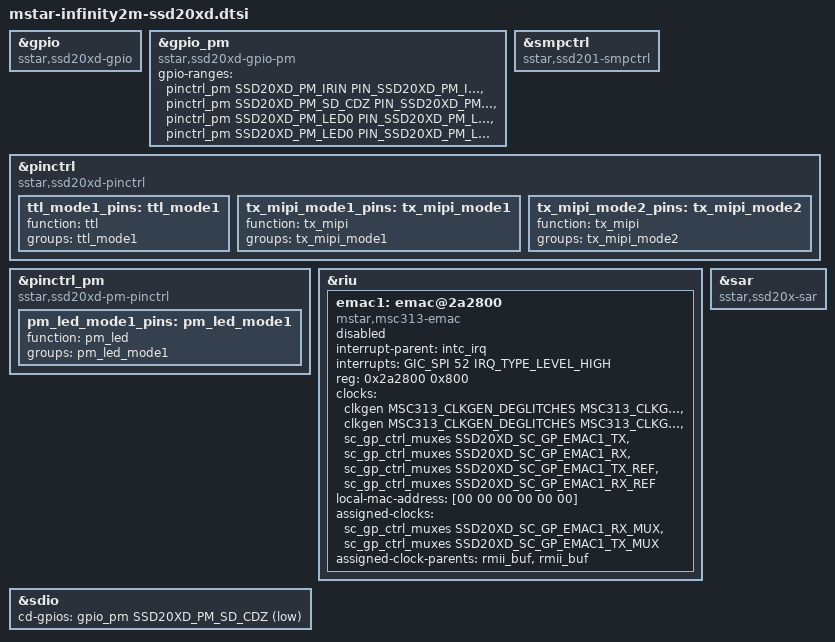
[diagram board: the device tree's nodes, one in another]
// SPDX-License-Identifier: GPL-2.0-or-later
/*
 * Copyright (c) 2020 thingy.jp.
 * Author: Daniel Palmer <daniel@thingy.jp>
 */

#include <dt-bindings/gpio/msc313-gpio-pm.h>
#include <dt-bindings/pinctrl/mstar.h>
#include <dt-bindings/clock/mstar-msc313-sc-gp.h>

#include "mstar-infinity2m.dtsi"

&gpio {
	compatible = "sstar,ssd20xd-gpio";
	/delete-property/ gpio-ranges;
	status = "okay";
};

&gpio_pm {
	compatible = "sstar,ssd20xd-gpio-pm";
	gpio-ranges = <&pinctrl_pm SSD20XD_PM_IRIN PIN_SSD20XD_PM_IRIN 1>,
		      <&pinctrl_pm SSD20XD_PM_SD_CDZ PIN_SSD20XD_PM_SD_CDZ 1>,
		      <&pinctrl_pm SSD20XD_PM_LED0 PIN_SSD20XD_PM_LED0 1>,
		      <&pinctrl_pm SSD20XD_PM_LED0 PIN_SSD20XD_PM_LED1 1>;
	/*interrupts-extended = <&intc_fiq GIC_SPI 23 IRQ_TYPE_LEVEL_HIGH>;*/
	status = "okay";
};

&smpctrl {
	compatible = "sstar,ssd201-smpctrl", "mstar,smpctrl";
	status = "okay";
};

&pinctrl {
	compatible = "sstar,ssd20xd-pinctrl";
	ttl_mode1_pins: ttl_mode1 {
		function = "ttl";
		groups = "ttl_mode1";
	};
	tx_mipi_mode1_pins: tx_mipi_mode1 {
		function = "tx_mipi";
		groups = "tx_mipi_mode1";
	};
	tx_mipi_mode2_pins: tx_mipi_mode2 {
		function = "tx_mipi";
		groups = "tx_mipi_mode2";
	};
};

&pinctrl_pm {
	compatible = "sstar,ssd20xd-pm-pinctrl";
	pm_led_mode1_pins: pm_led_mode1 {
		function = "pm_led";
		groups = "pm_led_mode1";
	};
};

&riu {
	emac1: emac@2a2800 {
		#address-cells = <1>;
		#size-cells = <0>;
		compatible = "mstar,msc313-emac";
		interrupt-parent = <&intc_irq>;
		interrupts = <GIC_SPI 52 IRQ_TYPE_LEVEL_HIGH>;
		reg = <0x2a2800 0x800>;
		clock-names = "pclk", "hclk", "tx_clk", "rx_clk", "tx_ref", "rx_ref";
		clocks = <&clkgen MSC313_CLKGEN_DEGLITCHES MSC313_CLKGEN_EMAC_AHB 0>,
			 <&clkgen MSC313_CLKGEN_DEGLITCHES MSC313_CLKGEN_EMAC_AHB 0>,
			 <&sc_gp_ctrl_muxes SSD20XD_SC_GP_EMAC1_TX>,
			 <&sc_gp_ctrl_muxes SSD20XD_SC_GP_EMAC1_RX>,
			 <&sc_gp_ctrl_muxes SSD20XD_SC_GP_EMAC1_TX_REF>,
			 <&sc_gp_ctrl_muxes SSD20XD_SC_GP_EMAC1_RX_REF>;
		local-mac-address = [00 00 00 00 00 00];
		status = "disabled";
		assigned-clocks = <&sc_gp_ctrl_muxes SSD20XD_SC_GP_EMAC1_RX_MUX>,
				  <&sc_gp_ctrl_muxes SSD20XD_SC_GP_EMAC1_TX_MUX>;
		assigned-clock-parents = <&rmii_buf>, <&rmii_buf>;
	};
};

&sar {
	compatible = "sstar,ssd20x-sar";
	status = "okay";
};

&sdio {
	cd-gpios = <&gpio_pm SSD20XD_PM_SD_CDZ GPIO_ACTIVE_LOW>;
};
